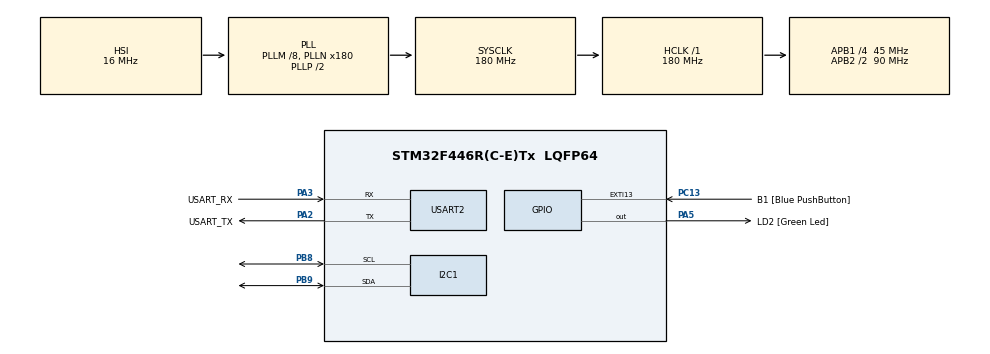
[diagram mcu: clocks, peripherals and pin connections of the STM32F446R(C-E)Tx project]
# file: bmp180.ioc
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Dma.I2C1_RX.0.Direction=DMA_PERIPH_TO_MEMORY
Dma.I2C1_RX.0.FIFOMode=DMA_FIFOMODE_DISABLE
Dma.I2C1_RX.0.Instance=DMA1_Stream0
Dma.I2C1_RX.0.MemDataAlignment=DMA_MDATAALIGN_BYTE
Dma.I2C1_RX.0.MemInc=DMA_MINC_ENABLE
Dma.I2C1_RX.0.Mode=DMA_NORMAL
Dma.I2C1_RX.0.PeriphDataAlignment=DMA_PDATAALIGN_BYTE
Dma.I2C1_RX.0.PeriphInc=DMA_PINC_DISABLE
Dma.I2C1_RX.0.Priority=DMA_PRIORITY_LOW
Dma.I2C1_TX.1.Direction=DMA_MEMORY_TO_PERIPH
Dma.I2C1_TX.1.FIFOMode=DMA_FIFOMODE_DISABLE
Dma.I2C1_TX.1.Instance=DMA1_Stream6
Dma.I2C1_TX.1.MemDataAlignment=DMA_MDATAALIGN_BYTE
Dma.I2C1_TX.1.MemInc=DMA_MINC_ENABLE
Dma.I2C1_TX.1.Mode=DMA_NORMAL
Dma.I2C1_TX.1.PeriphDataAlignment=DMA_PDATAALIGN_BYTE
Dma.I2C1_TX.1.PeriphInc=DMA_PINC_DISABLE
Dma.I2C1_TX.1.Priority=DMA_PRIORITY_LOW
Dma.Request0=I2C1_RX
Dma.Request1=I2C1_TX
Mcu.Family=STM32F4
Mcu.Name=STM32F446R(C-E)Tx
Mcu.Package=LQFP64
NVIC.DMA1_Stream0_IRQn=true\:0\:0\:false\:false\:true\:false\:true\:true
NVIC.DMA1_Stream6_IRQn=true\:0\:0\:false\:false\:true\:false\:true\:true
NVIC.PriorityGroup=NVIC_PRIORITYGROUP_0
PA13.GPIO_Label=TMS
PA13.Mode=Serial_Wire
PA13.Signal=SYS_JTMS-SWDIO
PA14.GPIO_Label=TCK
PA14.Mode=Serial_Wire
PA14.Signal=SYS_JTCK-SWCLK
PA2.GPIO_Label=USART_TX
PA2.Mode=Asynchronous
PA2.Signal=USART2_TX
PA3.GPIO_Label=USART_RX
PA3.Mode=Asynchronous
PA3.Signal=USART2_RX
PA5.GPIO_Label=LD2 [Green Led]
PA5.Signal=GPIO_Output
PB3.GPIO_Label=SWO
PB3.Signal=SYS_JTDO-SWO
PB8.Mode=I2C
PB8.Signal=I2C1_SCL
PB9.Mode=I2C
PB9.Signal=I2C1_SDA
PC13.GPIO_Label=B1 [Blue PushButton]
PC13.GPIO_ModeDefaultEXTI=GPIO_MODE_IT_FALLING
PC13.Signal=GPXTI13
PC14-OSC32_IN.Mode=LSE-External-Oscillator
PC14-OSC32_IN.Signal=RCC_OSC32_IN
PC15-OSC32_OUT.Mode=LSE-External-Oscillator
PC15-OSC32_OUT.Signal=RCC_OSC32_OUT
PH0-OSC_IN.Mode=HSE-External-Oscillator
PH0-OSC_IN.Signal=RCC_OSC_IN
PH1-OSC_OUT.Mode=HSE-External-Oscillator
PH1-OSC_OUT.Signal=RCC_OSC_OUT
ProjectManager.HeapSize=0x200
ProjectManager.StackSize=0x400
ProjectManager.TargetToolchain=STM32CubeIDE
RCC.48MHZClocksFreq_Value=84000000
RCC.AHBFreq_Value=180000000
RCC.APB1CLKDivider=RCC_HCLK_DIV4
RCC.APB1Freq_Value=45000000
RCC.APB1TimFreq_Value=90000000
RCC.APB2CLKDivider=RCC_HCLK_DIV2
RCC.APB2Freq_Value=90000000
RCC.APB2TimFreq_Value=180000000
RCC.CortexFreq_Value=180000000
RCC.FLatency-AdvancedSettings=FLASH_LATENCY_5
RCC.HCLKFreq_Value=180000000
RCC.HSE_VALUE=8000000
RCC.HSI_VALUE=16000000
RCC.PLLM=8
RCC.PLLN=180
RCC.SYSCLKFreq_VALUE=180000000
RCC.SYSCLKSource=RCC_SYSCLKSOURCE_PLLCLK
RCC.USBFreq_Value=180000000
RCC.VCOOutputFreq_Value=360000000
USART2.VirtualMode=VM_ASYNC
board=NUCLEO-F446RE

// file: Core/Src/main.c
/* USER CODE BEGIN Header */
/**
 ******************************************************************************
 * @file           : main.c
 * @brief      s    : Main program body
 ******************************************************************************
 * @attention
 *
 * Copyright (c) 2023 STMicroelectronics.
 * All rights reserved.
 *
 * This software is licensed under terms that can be found in the LICENSE file
 * in the root directory of this software component.
 * If no LICENSE file comes with this software, it is provided AS-IS.
 *
 ******************************************************************************
 */
/* USER CODE END Header */
#include "main.h"
#include "dma.h"
#include "i2c.h"
#include "usart.h"
#include "gpio.h"

/* USER CODE BEGIN Includes */
#include "bmp180_for_stm32_hal.h"
/* USER CODE END Includes */

/* USER CODE BEGIN PM */

#define p0 100955.0f

/* USER CODE END PM */

/* USER CODE BEGIN PV */
// deneme
uint8_t data[2];
void HAL_I2C_MemRxCpltCallback(I2C_HandleTypeDef *hi2c)
{
  HAL_I2C_Mem_Read_IT(&hi2c1, BMP180_I2C_ADDR << 1, BMP180_MSB_REG, 1, data, 2);
}

/* USER CODE END PV */

void SystemClock_Config(void);

int main(void)
{

  /* MCU Configuration--------------------------------------------------------*/

  /* Reset of all peripherals, Initializes the Flash interface and the Systick. */
  HAL_Init();

  /* Configure the system clock */
  SystemClock_Config();

  /* Initialize all configured peripherals */
  MX_GPIO_Init();
  MX_DMA_Init();
  MX_USART2_UART_Init();
  MX_I2C1_Init();
  /* USER CODE BEGIN 2 */

  /* Initializes BMP180 sensor and oversampling settings. */
  BMP180_Init(&hi2c1);
  BMP180_SetOversampling(BMP180_ULTRA);

  /* Update calibration data. Must be called once before entering main loop. */
  BMP180_UpdateCalibrationData();

  HAL_I2C_Mem_Read_IT(&hi2c1, BMP180_I2C_ADDR << 1, BMP180_MSB_REG, 1, data, 2);

  /* USER CODE END 2 */

  /* Infinite loop */
  /* USER CODE BEGIN WHILE */
  while (1)
  {
    /* Reads temperature. */
    // int32_t temperature = BMP180_GetRawTemperature();
    // float temperature = BMP180_GetTemperature();
    //
    /* Reads pressure. */
    // int32_t pressure = BMP180_GetPressure();

    // char buffer[100];

    /* Convert temperature to Kelvin */
    // float T = temperature / 10.0f + 273.15f;

    /* Calculate height using barometric formula */
    // float altitude = 44330 * (1- pow((pressure/p0), (1/5.255)) );

    // sprintf(buffer, "Temperature: %d.%d deg C\nPressure: %d Pa\nHeight: %f m\n", (int) temperature / 10, (int) temperature % 10, (int) pressure,(float) altitude);

    // HAL_UART_Transmit(&huart2, buffer, strlen(buffer), 1000);
    // HAL_Delay(250);

    /* USER CODE END WHILE */

  }
}

void SystemClock_Config(void)
{
  RCC_OscInitTypeDef RCC_OscInitStruct = {0};
  RCC_ClkInitTypeDef RCC_ClkInitStruct = {0};

  /** Configure the main internal regulator output voltage
   */
  __HAL_RCC_PWR_CLK_ENABLE();
  __HAL_PWR_VOLTAGESCALING_CONFIG(PWR_REGULATOR_VOLTAGE_SCALE1);

  /** Initializes the RCC Oscillators according to the specified parameters
   * in the RCC_OscInitTypeDef structure.
   */
  RCC_OscInitStruct.OscillatorType = RCC_OSCILLATORTYPE_HSI;
  RCC_OscInitStruct.HSIState = RCC_HSI_ON;
  RCC_OscInitStruct.HSICalibrationValue = RCC_HSICALIBRATION_DEFAULT;
  RCC_OscInitStruct.PLL.PLLState = RCC_PLL_ON;
  RCC_OscInitStruct.PLL.PLLSource = RCC_PLLSOURCE_HSI;
  RCC_OscInitStruct.PLL.PLLM = 8;
  RCC_OscInitStruct.PLL.PLLN = 180;
  RCC_OscInitStruct.PLL.PLLP = RCC_PLLP_DIV2;
  RCC_OscInitStruct.PLL.PLLQ = 2;
  RCC_OscInitStruct.PLL.PLLR = 2;
  if (HAL_RCC_OscConfig(&RCC_OscInitStruct) != HAL_OK)
  {
    Error_Handler();
  }

  /** Activate the Over-Drive mode
   */
  if (HAL_PWREx_EnableOverDrive() != HAL_OK)
  {
    Error_Handler();
  }

  /** Initializes the CPU, AHB and APB buses clocks
   */
  RCC_ClkInitStruct.ClockType = RCC_CLOCKTYPE_HCLK | RCC_CLOCKTYPE_SYSCLK | RCC_CLOCKTYPE_PCLK1 | RCC_CLOCKTYPE_PCLK2;
  RCC_ClkInitStruct.SYSCLKSource = RCC_SYSCLKSOURCE_PLLCLK;
  RCC_ClkInitStruct.AHBCLKDivider = RCC_SYSCLK_DIV1;
  RCC_ClkInitStruct.APB1CLKDivider = RCC_HCLK_DIV4;
  RCC_ClkInitStruct.APB2CLKDivider = RCC_HCLK_DIV2;

  if (HAL_RCC_ClockConfig(&RCC_ClkInitStruct, FLASH_LATENCY_5) != HAL_OK)
  {
    Error_Handler();
  }
}

void Error_Handler(void)
{
  __disable_irq();
  while (1)
  {
  }
}
